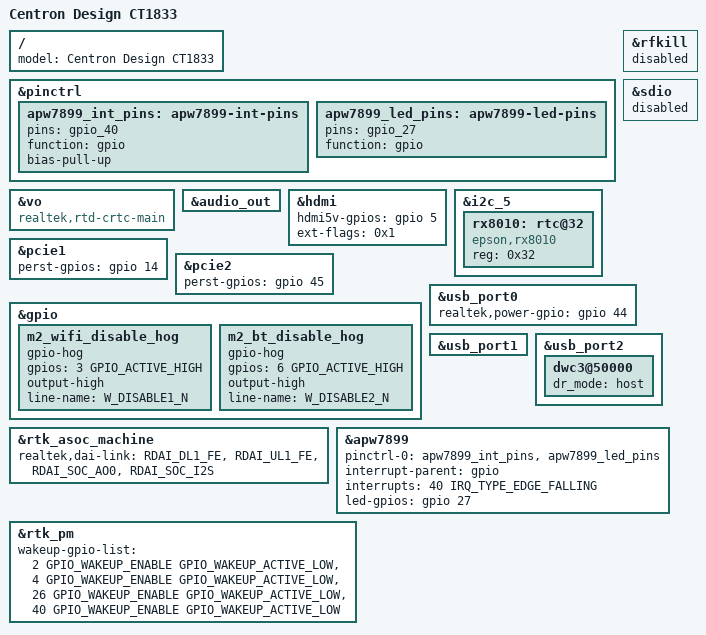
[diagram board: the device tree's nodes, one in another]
#include "rtd1619b-bleedingedge-2gb.dts"

&pinctrl {
	apw7899_int_pins: apw7899-int-pins {
		pins = "gpio_40";
		function = "gpio";
		bias-pull-up;
	};

	apw7899_led_pins: apw7899-led-pins {
		pins = "gpio_27";
		function = "gpio";
	};
};

/ {
	model = "Centron Design CT1833";
};

&vo {
	compatible = "realtek,rtd-crtc-main";
};

&audio_out {
	/delete-property/audio-gpios;
};

&hdmi {
	hdmi5v-gpios = <&gpio 5 GPIO_ACTIVE_HIGH>;
	ext-flags = <0x1>;
};

&i2c_5 {
	rx8010: rtc@32 {
		compatible = "epson,rx8010";
		reg = <0x32>;
	};
};

&pcie1 {
	perst-gpios = <&gpio 14 GPIO_ACTIVE_HIGH>;
};

&pcie2 {
	perst-gpios = <&gpio 45 GPIO_ACTIVE_HIGH>;
};

&rfkill {
	/delete-property/rfkill-gpios;
	status = "disabled";
};

&gpio {
	m2_wifi_disable_hog {
		gpio-hog;
		gpios = <3 GPIO_ACTIVE_HIGH>;
		output-high;
		line-name = "W_DISABLE1_N";
	};
	m2_bt_disable_hog {
		gpio-hog;
		gpios = <6 GPIO_ACTIVE_HIGH>;
		output-high;
		line-name = "W_DISABLE2_N";
	};
};

&sdio {
	/delete-property/wifi-rst-gpios;
	status = "disabled";
};

&rtk_asoc_machine {
	/delete-property/pinctrl-0;
	realtek,dai-link = "RDAI_DL1_FE", "RDAI_UL1_FE", "RDAI_SOC_AO0", "RDAI_SOC_I2S";
};

&usb_port0 {
	realtek,power-gpio = <&gpio 44 GPIO_ACTIVE_HIGH>;
};

&usb_port1 {
	/delete-property/realtek,power-gpio;
};

&usb_port2 {
	/delete-property/realtek,power-gpio;
	dwc3@50000 {
		dr_mode = "host"; /* otg, host, peripheral*/
		/delete-property/usb-role-switch;
		/delete-property/role-switch-default-mode;
	};
};

/delete-node/ &type_c;

&apw7899 {
	pinctrl-names = "default";
	pinctrl-0 = <&apw7899_int_pins &apw7899_led_pins>;
	interrupt-parent = <&gpio>;

	/*
	 * gpio_40 is on the PMIC /INT pin: open-drain, active-low, latched.
	 * It drops when the PMIC latches a pwrkey event and returns high
	 * (pull-up above) only after the handler writes REG00.INT = 0.
	 * Falling edge only - one IRQ per PMIC event (IT, then LP).
	 */
	interrupts = <40 IRQ_TYPE_EDGE_FALLING>;

	/* gpio_27: LED output */
	led-gpios = <&gpio 27 GPIO_ACTIVE_HIGH>;
};

&rtk_pm {
	wakeup-gpio-list = <2  GPIO_WAKEUP_ENABLE GPIO_WAKEUP_ACTIVE_LOW>,
			   <4  GPIO_WAKEUP_ENABLE GPIO_WAKEUP_ACTIVE_LOW>,
			   <26 GPIO_WAKEUP_ENABLE GPIO_WAKEUP_ACTIVE_LOW>,
			   <40 GPIO_WAKEUP_ENABLE GPIO_WAKEUP_ACTIVE_LOW>;
};
